VERSION ""

NS_ :

BS_:

BU_: ADASM GatewayA

BO_ 768 MSG_ObjectDetection: 2 ADASM
 SG_ SIG_PrecedingCarPos : 8|2@1+ (1,0) [0|3] ""  GatewayA
 SG_ SIG_Depending : 0|8@1+ (1,0) [0|255] ""  GatewayA

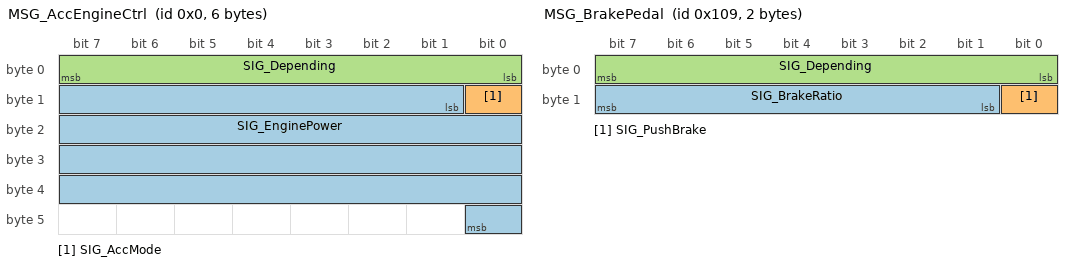
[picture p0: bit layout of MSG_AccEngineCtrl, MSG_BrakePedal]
BO_ 0 MSG_AccEngineCtrl: 6 ADASM
 SG_ SIG_EnginePower : 9|32@1- (1,0) [-3.4E+038|3.4E+038] ""  GatewayA
 SG_ SIG_AccMode : 8|1@1+ (1,0) [0|1] ""  GatewayA
 SG_ SIG_Depending : 0|8@1+ (1,0) [0|255] ""  GatewayA

BO_ 517 MSG_RealSpeed: 2 GatewayA
 SG_ SIG_VehicleSpeed : 8|8@1+ (1,0) [0|250] "km/h"  ADASM
 SG_ SIG_Depending : 0|8@1+ (1,0) [0|255] ""  ADASM

BO_ 265 MSG_BrakePedal: 2 GatewayA
 SG_ SIG_BrakeRatio : 9|7@1+ (1,0) [0|100] "%"  ADASM
 SG_ SIG_PushBrake : 8|1@1+ (1,0) [0|1] ""  ADASM
 SG_ SIG_Depending : 0|8@1+ (1,0) [0|255] ""  ADASM

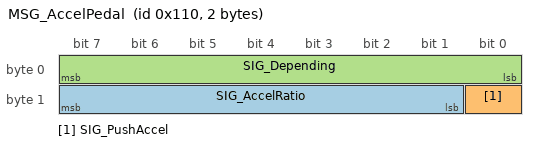
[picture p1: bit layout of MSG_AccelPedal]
BO_ 272 MSG_AccelPedal: 2 GatewayA
 SG_ SIG_AccelRatio : 9|7@1+ (1,0) [0|100] "%"  ADASM
 SG_ SIG_PushAccel : 8|1@1+ (1,0) [0|1] ""  ADASM
 SG_ SIG_Depending : 0|8@1+ (1,0) [0|255] ""  ADASM

SIG_VALTYPE_ 0 SIG_EnginePower : 1;
